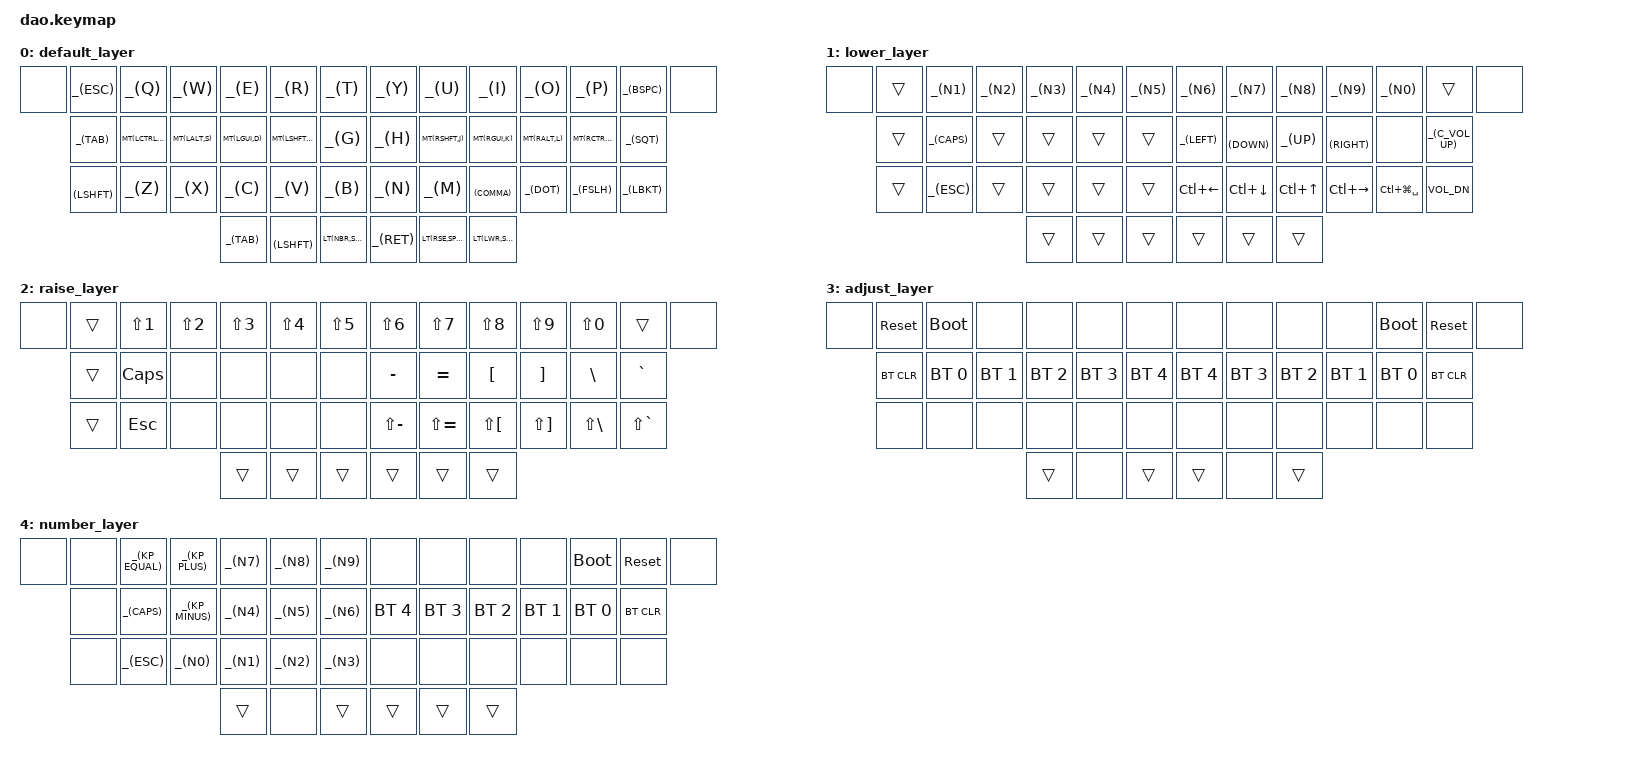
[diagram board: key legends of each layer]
/*
 * Copyright (c) 2021 Margar Ag
 *
 * SPDX-License-Identifier: MIT
 */

#include <behaviors.dtsi>
#include <dt-bindings/zmk/keys.h>
#include <dt-bindings/zmk/bt.h>

#define DEF 0
#define LWR 1
#define RSE 2
#define ADJ 3
#define NBR 4
#define XXXX &none
#define TTTT &trans
#define MT(MOD, TAP) &u_mt MOD TAP
#define LT(LAYER, TAP) &u_lt LAYER TAP
#define __(KEY) &kp KEY
#define U_TAPPING_TERM 200
#define C__A MT(LCTRL,A)
#define A__S MT(LALT,S)
#define G__D MT(LGUI,D)
#define S__F MT(LSHFT,F)
#define S__J MT(RSHFT,J)
#define G__K MT(RGUI,K)
#define S__F MT(LSHFT,F)
#define A__L MT(RALT,L)
#define C__SEMI MT(RCTRL,SEMI)


&lt { quick_tap_ms = <200>; };
&mt { quick_tap_ms = <200>; };

/ {
    behaviors {
        u_mt: u_mt {
          compatible = "zmk,behavior-hold-tap";
          label = "u_mt";
          #binding-cells = <2>;
          tapping_term_ms = <U_TAPPING_TERM>;
          flavor = "tap-preferred";
          bindings = <&kp>, <&kp>;
        };
        u_lt: u_lt {
          compatible = "zmk,behavior-hold-tap";
          label = "u_lt";
          #binding-cells = <2>;
          tapping_term_ms = <U_TAPPING_TERM>;
          flavor = "tap-preferred";
          bindings = <&mo>, <&kp>;
        };
    };
    keymap {
        compatible = "zmk,keymap";
        default_layer {
            bindings = <
      XXXX  __(ESC)    __(Q)       __(W)      __(E)      __(R)       __(T)      __(Y)    __(U)          __(I)      __(O)      __(P)          __(BSPC)  XXXX
            __(TAB)    MT(LCTRL,A) MT(LALT,S) MT(LGUI,D) MT(LSHFT,F) __(G)      __(H)    MT(RSHFT,J)    MT(RGUI,K) MT(RALT,L) MT(RCTRL,SEMI) __(SQT)
            __(LSHFT)  __(Z)       __(X)      __(C)      __(V)       __(B)      __(N)    __(M)          __(COMMA)  __(DOT)    __(FSLH)       __(LBKT)
                                         __(TAB)  __(LSHFT)  LT(NBR,SPACE)      __(RET)  LT(RSE,SPACE)  LT(LWR,SPACE)
            >;
        };
        lower_layer {
            bindings = <
      XXXX  TTTT    __(N1)      __(N2)    __(N3)    __(N4)    __(N5)         __(N6)        __(N7)        __(N8)      __(N9)         __(N0)           TTTT           XXXX
            TTTT    __(CAPS)      TTTT      TTTT      TTTT      TTTT         __(LEFT)      __(DOWN)      __(UP)      __(RIGHT)      XXXX              __(C_VOL_UP)
            TTTT    __(ESC)       TTTT      TTTT      TTTT      TTTT         &kp LC(LEFT)  &kp LC(DOWN)  &kp LC(UP)  &kp LC(RIGHT)  &kp LC(LG(SPC))  &kp C_VOL_DN
                                            TTTT      TTTT      TTTT         TTTT          TTTT          TTTT
            >;
        };
        raise_layer {
            bindings = <
      XXXX  TTTT  &kp LS(N1) &kp LS(N2) &kp LS(N3)  &kp LS(N4)  &kp LS(N5)         &kp LS(N6)     &kp LS(N7)     &kp LS(N8)    &kp LS(N9)    &kp LS(N0)    TTTT          XXXX
            TTTT  &kp CAPS   XXXX       XXXX        XXXX        XXXX               &kp MINUS      &kp EQUAL      &kp LBKT      &kp RBKT      &kp BSLH      &kp GRAVE
            TTTT  &kp ESC    XXXX       XXXX        XXXX        XXXX               &kp LS(MINUS)  &kp LS(EQUAL)  &kp LS(LBKT)  &kp LS(RBKT)  &kp LS(BSLH)  &kp LS(GRAVE)
                                        TTTT        TTTT        TTTT               TTTT           TTTT           TTTT
            >;
        };
        adjust_layer {
            bindings = <
     XXXX   &sys_reset   &bootloader    XXXX          XXXX          XXXX          XXXX               XXXX          XXXX          XXXX          XXXX          &bootloader   &sys_reset  XXXX
            &bt BT_CLR   &bt BT_SEL 0   &bt BT_SEL 1  &bt BT_SEL 2  &bt BT_SEL 3  &bt BT_SEL 4       &bt BT_SEL 4  &bt BT_SEL 3  &bt BT_SEL 2  &bt BT_SEL 1  &bt BT_SEL 0  &bt BT_CLR
            XXXX         XXXX           XXXX          XXXX          XXXX          XXXX               XXXX          XXXX          XXXX          XXXX          XXXX          XXXX
                                                      TTTT          XXXX          TTTT               TTTT          XXXX          TTTT
            >;
        };
        number_layer {
            bindings = <
      XXXX  XXXX  __(KP_EQUAL)  __(KP_PLUS)   __(N7)  __(N8)  __(N9)         XXXX          XXXX          XXXX          XXXX          &bootloader   &sys_reset  XXXX
            XXXX  __(CAPS)      __(KP_MINUS)  __(N4)  __(N5)  __(N6)         &bt BT_SEL 4  &bt BT_SEL 3  &bt BT_SEL 2  &bt BT_SEL 1  &bt BT_SEL 0  &bt BT_CLR
            XXXX  __(ESC)       __(N0)        __(N1)  __(N2)  __(N3)         XXXX          XXXX          XXXX          XXXX          XXXX          XXXX
                                                TTTT    XXXX    TTTT         TTTT          TTTT          TTTT
            >;
        };
    };
};
